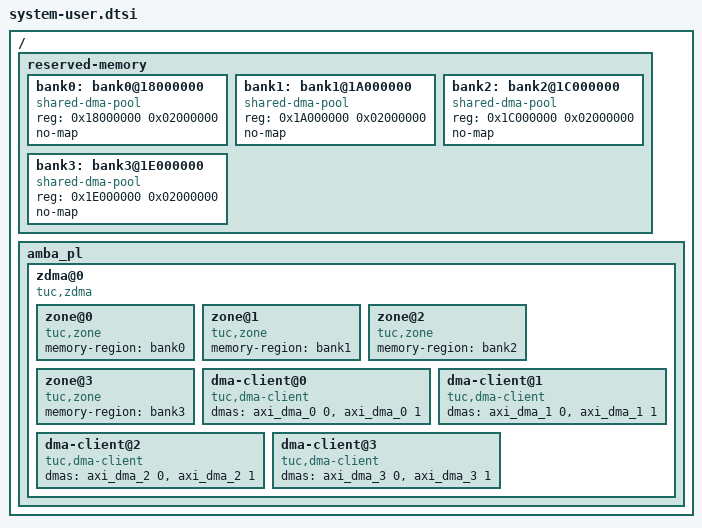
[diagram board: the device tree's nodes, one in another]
/include/ "system-conf.dtsi"
/  {
	reserved-memory {
		#address-cells = <1>;
		#size-cells = <1>;
		ranges;

		bank0: bank0@18000000 {
			reg = <0x18000000 0x02000000>;
			compatible = "shared-dma-pool";
			no-map;
		};
		bank1: bank1@1A000000 {
			reg = <0x1A000000 0x02000000>;
			compatible = "shared-dma-pool";
			no-map;
		};
		bank2: bank2@1C000000 {
			reg = <0x1C000000 0x02000000>;
			compatible = "shared-dma-pool";
			no-map;
		};
		bank3: bank3@1E000000 {
			reg = <0x1E000000 0x02000000>;
			compatible = "shared-dma-pool";
			no-map;
		};
	};

	amba_pl {
		zdma@0 {
			compatible = "tuc,zdma";

			zone@0 {
				compatible = "tuc,zone";
				memory-region = <&bank0>;
			};
			zone@1 {
				compatible = "tuc,zone";
				memory-region = <&bank1>;
			};
			zone@2 {
				compatible = "tuc,zone";
				memory-region = <&bank2>;
			};
			zone@3 {
				compatible = "tuc,zone";
				memory-region = <&bank3>;
			};

			dma-client@0 {
				compatible = "tuc,dma-client";
				dmas = <&axi_dma_0 0
					&axi_dma_0 1>;
				dma-names = "tx", "rx";
			};
			dma-client@1 {
				compatible = "tuc,dma-client";
				dmas = <&axi_dma_1 0
					&axi_dma_1 1>;
				dma-names = "tx", "rx";
			};
			dma-client@2 {
				compatible = "tuc,dma-client";
				dmas = <&axi_dma_2 0
					&axi_dma_2 1>;
				dma-names = "tx", "rx";
			};
			dma-client@3 {
				compatible = "tuc,dma-client";
				dmas = <&axi_dma_3 0
					&axi_dma_3 1>;
				dma-names = "tx", "rx";
			};
		};
	};
};

